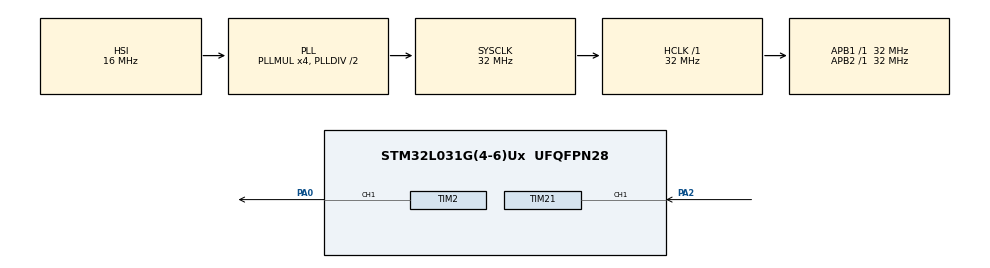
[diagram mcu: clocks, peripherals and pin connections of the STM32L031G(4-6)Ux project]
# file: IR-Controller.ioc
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Mcu.Family=STM32L0
Mcu.Name=STM32L031G(4-6)Ux
Mcu.Package=UFQFPN28
NVIC.TIM21_IRQn=true\:0\:0\:false\:false\:true\:true\:true\:true
NVIC.TIM22_IRQn=true\:0\:0\:false\:false\:true\:true\:true\:true
PA0-CK_IN.Signal=S_TIM2_CH1
PA13.Mode=Serial_Wire
PA13.Signal=SYS_SWDIO
PA14.Mode=Serial_Wire
PA14.Signal=SYS_SWCLK
PA2.Signal=S_TIM21_CH1
ProjectManager.HeapSize=0x200
ProjectManager.StackSize=0x400
ProjectManager.TargetToolchain=MDK-ARM V5.32
RCC.AHBFreq_Value=32000000
RCC.APB1Freq_Value=32000000
RCC.APB1TimFreq_Value=32000000
RCC.APB2Freq_Value=32000000
RCC.APB2TimFreq_Value=32000000
RCC.HCLKFreq_Value=32000000
RCC.HSE_VALUE=8000000
RCC.HSI16_VALUE=16000000
RCC.HSI_VALUE=16000000
RCC.LSE_VALUE=32768
RCC.MSI_VALUE=2097000
RCC.PLLMUL=RCC_PLLMUL_4
RCC.SYSCLKFreq_VALUE=32000000
RCC.SYSCLKSource=RCC_SYSCLKSOURCE_PLLCLK
RCC.VCOOutputFreq_Value=64000000
SH.S_TIM21_CH1.0=TIM21_CH1,Input_Capture1_from_TI1
SH.S_TIM2_CH1.0=TIM2_CH1,PWM Generation1 CH1
TIM2.Channel-PWM\ Generation1\ CH1=TIM_CHANNEL_1
TIM2.Period=841
TIM21.AutoReloadPreload=TIM_AUTORELOAD_PRELOAD_DISABLE
TIM21.Channel-Input_Capture1_from_TI1=TIM_CHANNEL_1
TIM21.ICPolarity_CH1=TIM_INPUTCHANNELPOLARITY_FALLING
TIM21.Period=65535
TIM21.Prescaler=31
TIM21.TIM_MasterSlaveMode=TIM_MASTERSLAVEMODE_DISABLE
TIM22.Prescaler=31
VP_TIM21_VS_ClockSourceINT.Mode=Internal
VP_TIM22_VS_ClockSourceINT.Mode=Internal
board=custom

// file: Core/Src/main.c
/* USER CODE BEGIN Header */
/**
  ******************************************************************************
  * @file           : main.c
  * @brief          : Main program body
  ******************************************************************************
  * @attention
  *
  * Copyright (c) 2024 STMicroelectronics.
  * All rights reserved.
  *
  * This software is licensed under terms that can be found in the LICENSE file
  * in the root directory of this software component.
  * If no LICENSE file comes with this software, it is provided AS-IS.
  *
  ******************************************************************************
  */
/* USER CODE END Header */
#include "main.h"

/* USER CODE BEGIN Includes */
#include "math.h"
/* USER CODE END Includes */

/* USER CODE BEGIN PTD */
#include "IR_code.h"
/* USER CODE END PTD */

TIM_HandleTypeDef htim2;
TIM_HandleTypeDef htim21;
TIM_HandleTypeDef htim22;

void SystemClock_Config(void);
static void MX_GPIO_Init(void);
static void MX_TIM21_Init(void);
static void MX_TIM2_Init(void);
static void MX_TIM22_Init(void);
/* USER CODE BEGIN PFP */
void InfraredSend(uint8_t BitValue_IN[],uint16_t KeepTime_IN[],uint32_t SampleCount_IN);
void HAL_Delay_Us(uint32_t Delay_us) ;
/* USER CODE END PFP */

/* USER CODE BEGIN 0 */
uint8_t send = 0;

uint8_t gu8BitVal = 0;
uint16_t KeepTime[400] = {0};
uint8_t BitValue[400] = {0};
uint32_t SampleCount = 0;
uint32_t NowTimCnt = 0;
enum State {NONE_STATE=0,RECV_STATE,END_STATE} state;
/* USER CODE END 0 */

int main(void)
{

  /* MCU Configuration--------------------------------------------------------*/

  /* Reset of all peripherals, Initializes the Flash interface and the Systick. */
  HAL_Init();

  /* Configure the system clock */
  SystemClock_Config();

  /* Initialize all configured peripherals */
  MX_GPIO_Init();
  MX_TIM21_Init();
  MX_TIM2_Init();
  MX_TIM22_Init();
  /* USER CODE BEGIN 2 */
	TIM2->CCR1 = 0;
	HAL_TIM_PWM_Start(&htim2, TIM_CHANNEL_1);
	HAL_TIM_Base_Start_IT(&htim21);
	HAL_TIM_IC_Start_IT(&htim21, TIM_CHANNEL_1); // start input capture
  /* USER CODE END 2 */

  /* Infinite loop */
  while (1)
  {

    /* USER CODE BEGIN 3 */
		InfraredSend(BitValue_Hisense_ON,KeepTime_Hisense_ON,SampleCount_Hisense_ON);
		HAL_Delay(10000);
		InfraredSend(BitValue_Hisense_OFF,KeepTime_Hisense_OFF,SampleCount_Hisense_OFF);
		HAL_Delay(10000);
		InfraredSend(BitValue_Haier_ON,KeepTime_Haier_ON,SampleCount_Haier_ON);
		HAL_Delay(10000);
		InfraredSend(BitValue_Haier_OFF,KeepTime_Haier_OFF,SampleCount_Haier_OFF);

  }
  /* USER CODE END 3 */
}

void SystemClock_Config(void)
{
  RCC_OscInitTypeDef RCC_OscInitStruct = {0};
  RCC_ClkInitTypeDef RCC_ClkInitStruct = {0};

  /** Configure the main internal regulator output voltage
  */
  __HAL_PWR_VOLTAGESCALING_CONFIG(PWR_REGULATOR_VOLTAGE_SCALE1);

  /** Initializes the RCC Oscillators according to the specified parameters
  * in the RCC_OscInitTypeDef structure.
  */
  RCC_OscInitStruct.OscillatorType = RCC_OSCILLATORTYPE_HSI;
  RCC_OscInitStruct.HSIState = RCC_HSI_ON;
  RCC_OscInitStruct.HSICalibrationValue = RCC_HSICALIBRATION_DEFAULT;
  RCC_OscInitStruct.PLL.PLLState = RCC_PLL_ON;
  RCC_OscInitStruct.PLL.PLLSource = RCC_PLLSOURCE_HSI;
  RCC_OscInitStruct.PLL.PLLMUL = RCC_PLLMUL_4;
  RCC_OscInitStruct.PLL.PLLDIV = RCC_PLLDIV_2;
  if (HAL_RCC_OscConfig(&RCC_OscInitStruct) != HAL_OK)
  {
    Error_Handler();
  }

  /** Initializes the CPU, AHB and APB buses clocks
  */
  RCC_ClkInitStruct.ClockType = RCC_CLOCKTYPE_HCLK|RCC_CLOCKTYPE_SYSCLK
                              |RCC_CLOCKTYPE_PCLK1|RCC_CLOCKTYPE_PCLK2;
  RCC_ClkInitStruct.SYSCLKSource = RCC_SYSCLKSOURCE_PLLCLK;
  RCC_ClkInitStruct.AHBCLKDivider = RCC_SYSCLK_DIV1;
  RCC_ClkInitStruct.APB1CLKDivider = RCC_HCLK_DIV1;
  RCC_ClkInitStruct.APB2CLKDivider = RCC_HCLK_DIV1;

  if (HAL_RCC_ClockConfig(&RCC_ClkInitStruct, FLASH_LATENCY_1) != HAL_OK)
  {
    Error_Handler();
  }
  HAL_RCC_MCOConfig(RCC_MCO1, RCC_MCO1SOURCE_SYSCLK, RCC_MCODIV_1);
}

static void MX_TIM2_Init(void)
{

  TIM_MasterConfigTypeDef sMasterConfig = {0};
  TIM_OC_InitTypeDef sConfigOC = {0};

  htim2.Instance = TIM2;
  htim2.Init.Prescaler = 0;
  htim2.Init.CounterMode = TIM_COUNTERMODE_UP;
  htim2.Init.Period = 841;
  htim2.Init.ClockDivision = TIM_CLOCKDIVISION_DIV1;
  htim2.Init.AutoReloadPreload = TIM_AUTORELOAD_PRELOAD_DISABLE;
  if (HAL_TIM_PWM_Init(&htim2) != HAL_OK)
  {
    Error_Handler();
  }
  sMasterConfig.MasterOutputTrigger = TIM_TRGO_RESET;
  sMasterConfig.MasterSlaveMode = TIM_MASTERSLAVEMODE_DISABLE;
  if (HAL_TIMEx_MasterConfigSynchronization(&htim2, &sMasterConfig) != HAL_OK)
  {
    Error_Handler();
  }
  sConfigOC.OCMode = TIM_OCMODE_PWM1;
  sConfigOC.Pulse = 0;
  sConfigOC.OCPolarity = TIM_OCPOLARITY_HIGH;
  sConfigOC.OCFastMode = TIM_OCFAST_DISABLE;
  if (HAL_TIM_PWM_ConfigChannel(&htim2, &sConfigOC, TIM_CHANNEL_1) != HAL_OK)
  {
    Error_Handler();
  }
  HAL_TIM_MspPostInit(&htim2);

}

static void MX_TIM21_Init(void)
{

  TIM_ClockConfigTypeDef sClockSourceConfig = {0};
  TIM_MasterConfigTypeDef sMasterConfig = {0};
  TIM_IC_InitTypeDef sConfigIC = {0};

  htim21.Instance = TIM21;
  htim21.Init.Prescaler = 31;
  htim21.Init.CounterMode = TIM_COUNTERMODE_UP;
  htim21.Init.Period = 65535;
  htim21.Init.ClockDivision = TIM_CLOCKDIVISION_DIV1;
  htim21.Init.AutoReloadPreload = TIM_AUTORELOAD_PRELOAD_DISABLE;
  if (HAL_TIM_Base_Init(&htim21) != HAL_OK)
  {
    Error_Handler();
  }
  sClockSourceConfig.ClockSource = TIM_CLOCKSOURCE_INTERNAL;
  if (HAL_TIM_ConfigClockSource(&htim21, &sClockSourceConfig) != HAL_OK)
  {
    Error_Handler();
  }
  if (HAL_TIM_IC_Init(&htim21) != HAL_OK)
  {
    Error_Handler();
  }
  sMasterConfig.MasterOutputTrigger = TIM_TRGO_RESET;
  sMasterConfig.MasterSlaveMode = TIM_MASTERSLAVEMODE_DISABLE;
  if (HAL_TIMEx_MasterConfigSynchronization(&htim21, &sMasterConfig) != HAL_OK)
  {
    Error_Handler();
  }
  sConfigIC.ICPolarity = TIM_INPUTCHANNELPOLARITY_FALLING;
  sConfigIC.ICSelection = TIM_ICSELECTION_DIRECTTI;
  sConfigIC.ICPrescaler = TIM_ICPSC_DIV1;
  sConfigIC.ICFilter = 0;
  if (HAL_TIM_IC_ConfigChannel(&htim21, &sConfigIC, TIM_CHANNEL_1) != HAL_OK)
  {
    Error_Handler();
  }

}

static void MX_TIM22_Init(void)
{

  TIM_ClockConfigTypeDef sClockSourceConfig = {0};
  TIM_MasterConfigTypeDef sMasterConfig = {0};

  htim22.Instance = TIM22;
  htim22.Init.Prescaler = 31;
  htim22.Init.CounterMode = TIM_COUNTERMODE_UP;
  htim22.Init.Period = 65535;
  htim22.Init.ClockDivision = TIM_CLOCKDIVISION_DIV1;
  htim22.Init.AutoReloadPreload = TIM_AUTORELOAD_PRELOAD_DISABLE;
  if (HAL_TIM_Base_Init(&htim22) != HAL_OK)
  {
    Error_Handler();
  }
  sClockSourceConfig.ClockSource = TIM_CLOCKSOURCE_INTERNAL;
  if (HAL_TIM_ConfigClockSource(&htim22, &sClockSourceConfig) != HAL_OK)
  {
    Error_Handler();
  }
  sMasterConfig.MasterOutputTrigger = TIM_TRGO_RESET;
  sMasterConfig.MasterSlaveMode = TIM_MASTERSLAVEMODE_DISABLE;
  if (HAL_TIMEx_MasterConfigSynchronization(&htim22, &sMasterConfig) != HAL_OK)
  {
    Error_Handler();
  }

}

static void MX_GPIO_Init(void)
{

  /* GPIO Ports Clock Enable */
  __HAL_RCC_GPIOA_CLK_ENABLE();

}

/* USER CODE BEGIN 4 */
void HAL_Delay_Us(uint32_t Delay_us)
{
		__HAL_TIM_SetCounter(&htim22, 0);
		__HAL_TIM_ENABLE(&htim22);
		while(__HAL_TIM_GetCounter(&htim22) < Delay_us);
		/* Disable the Peripheral */
		__HAL_TIM_DISABLE(&htim22);
}

void HAL_TIM_IC_CaptureCallback(TIM_HandleTypeDef *htim)
{
		if(htim->Channel == HAL_TIM_ACTIVE_CHANNEL_1)
		{
			if(TIM21->CCER & (TIM_CCER_CC1P))
			{
					TIM21->CCER &= ~(TIM_CCER_CC1P);
					gu8BitVal = 1;
			}
			else
			{
					TIM21->CCER |= TIM_CCER_CC1P;
					gu8BitVal = 0;
			}

			if(state == NONE_STATE)
			{
					__HAL_TIM_ENABLE(&htim22);
					state = RECV_STATE;
			}
			else if(state == RECV_STATE)
			{
					NowTimCnt = HAL_TIM_ReadCapturedValue(&htim21, TIM_CHANNEL_1);
					KeepTime[SampleCount] = round(NowTimCnt);
					BitValue[SampleCount ++] = gu8BitVal;
			}

			TIM21->CNT = 0;

		}
}

void HAL_TIM_PeriodElapsedCallback(TIM_HandleTypeDef *htim)
{
    if(htim == &htim21)
    {
        if(state == RECV_STATE)
        {
            state = END_STATE;
        }
    }
}

void InfraredSend(uint8_t BitValue_IN[],uint16_t KeepTime_IN[],uint32_t SampleCount_IN){
//	if(send == 1){
		uint16_t Count = 0;

    while(Count < SampleCount_IN )
    {
        if(BitValue_IN[Count] == 0)
        {
            TIM2->CCR1 = 420;//??38KHz,????50%?PWM?
            HAL_Delay_Us(KeepTime_IN[Count]);
            TIM2->CCR1 = 0;
        }
        else
        {
            TIM2->CCR1 = 0;
            HAL_Delay_Us(KeepTime_IN[Count]);
            TIM2->CCR1 = 0;
        }

        Count ++;
    }
//		send = 0;
//	}
}
/* USER CODE END 4 */

void Error_Handler(void)
{
  __disable_irq();
  while (1)
  {
  }
}
